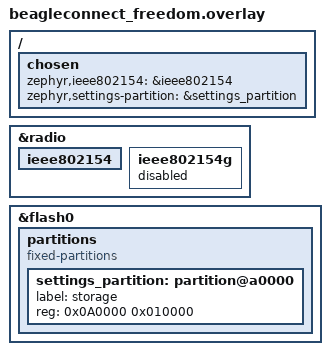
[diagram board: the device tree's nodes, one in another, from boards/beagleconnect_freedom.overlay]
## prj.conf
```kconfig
# SPDX-License-Identifier: Apache-2.0

# Increased main stack size required for initialization
CONFIG_MAIN_STACK_SIZE=4096

# Enable Networking and OpenThread stack
CONFIG_NETWORKING=y
CONFIG_NET_L2_OPENTHREAD=y
CONFIG_IEEE802154=y
CONFIG_OPENTHREAD=y
CONFIG_IEEE802154_CC13XX_CC26XX=y
CONFIG_OPENTHREAD_JOINER=y
CONFIG_OPENTHREAD_COMMISSIONER=y
CONFIG_OPENTHREAD_FTD=y
# Use NVS as settings backend
CONFIG_NVS=y

# Logging
CONFIG_LOG=y
CONFIG_NET_LOG=y
CONFIG_LOG_PRINTK=y

# Networking and OpenThread shells
CONFIG_SHELL=y
CONFIG_NET_SHELL=y
CONFIG_OPENTHREAD_SHELL=y



# Enable Zephyr’s Settings subsystem
CONFIG_SETTINGS=y

# Use the NVS (non-volatile storage) back end
CONFIG_SETTINGS_NVS=y

# Ensure runtime APIs are available
CONFIG_SETTINGS_RUNTIME=y

CONFIG_OPENTHREAD_MANUAL_START=y
```

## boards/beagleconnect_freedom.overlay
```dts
/* beagleconnect_freedom.overlay */

/ {
    chosen {
        zephyr,ieee802154     = &ieee802154;
        zephyr,settings-partition = &settings_partition;
    };
};

&radio {
    status = "okay";

    ieee802154 {
        status = "okay";
    };

    ieee802154g {
        status = "disabled";
    };
};

&flash0 {
    partitions {
        compatible = "fixed-partitions";
        #address-cells = <1>;
        #size-cells    = <1>;

        /* 64 KiB for OpenThread settings: 0xA0000–0xB0000 */
        settings_partition: partition@a0000 {
            label = "storage";
            reg   = <0x0A0000 0x010000>;
        };
    };
};
```

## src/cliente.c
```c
#include <zephyr.h>
#include <net/socket.h>

void send_thread_message(void)
{
    int sock;
    struct sockaddr_in6 peer = {0};
    const char *msg = "¡Hola desde Zephyr!";
    int err;

    sock = socket(AF_INET6, SOCK_DGRAM, IPPROTO_UDP);
    if (sock < 0) {
        printk("Error al crear socket: %d\n", sock);
        return;
    }

    peer.sin6_family = AF_INET6;
    net_addr_pton(AF_INET6, "fd11:22:33:44::2", &peer.sin6_addr);
    peer.sin6_port = htons(1234);

    err = sendto(sock, msg, strlen(msg), 0,
                 (struct sockaddr *)&peer, sizeof(peer));
    if (err < 0) {
        printk("Error enviando: %d\n", err);
    } else {
        printk("Enviado %d bytes\n", err);
    }

    close(sock);
}
```

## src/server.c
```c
#include <zephyr.h>
#include <net/socket.h>
#include <logging/log.h>

LOG_MODULE_REGISTER(udp_receiver, LOG_LEVEL_INF);

#define LISTEN_PORT 1234

void main(void)
{
    int sock;
    struct sockaddr_in6 local_addr = { 0 };
    char buf[128];
    struct sockaddr_in6 src_addr;
    socklen_t addr_len = sizeof(src_addr);
    int len;

    /* 1) Crear y bindear el socket UDP */
    sock = socket(AF_INET6, SOCK_DGRAM, IPPROTO_UDP);
    if (sock < 0) {
        LOG_ERR("socket() failed: %d", sock);
        return;
    }

    local_addr.sin6_family = AF_INET6;
    local_addr.sin6_addr = in6addr_any;
    local_addr.sin6_port = htons(LISTEN_PORT);

    if (bind(sock, (struct sockaddr *)&local_addr, sizeof(local_addr)) < 0) {
        LOG_ERR("bind() failed: %d", errno);
        close(sock);
        return;
    }

    LOG_INF("Esperando mensajes en puerto %d …", LISTEN_PORT);

    /* 2) Bucle de recepción */
    while (1) {
        len = recvfrom(sock, buf, sizeof(buf)-1, 0,
                       (struct sockaddr *)&src_addr, &addr_len);
        if (len < 0) {
            LOG_ERR("recvfrom() failed: %d", len);
            break;
        }
        buf[len] = '\0';
        char addr_str[INET6_ADDRSTRLEN];
        net_addr_ntop(AF_INET6, &src_addr.sin6_addr, addr_str, sizeof(addr_str));
        LOG_INF("Recibido %d bytes de [%s]:%d: \"%s\"",
                len, addr_str, ntohs(src_addr.sin6_port), buf);
    }

    close(sock);
}
```
